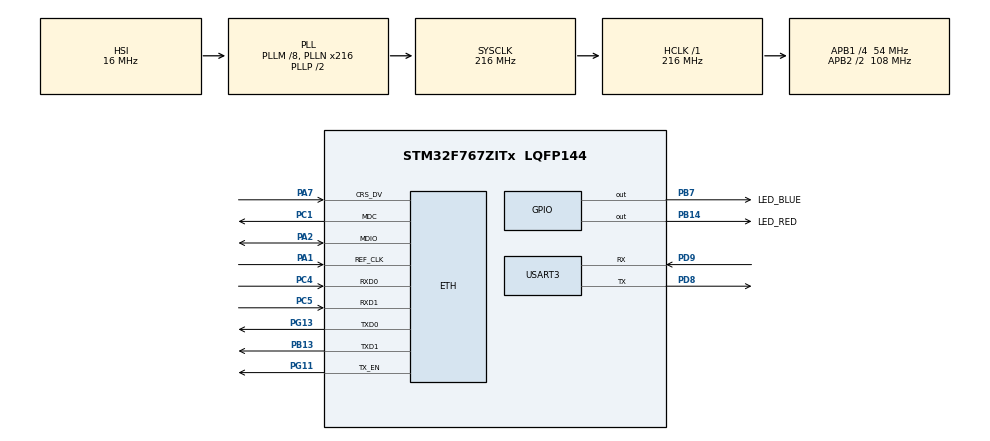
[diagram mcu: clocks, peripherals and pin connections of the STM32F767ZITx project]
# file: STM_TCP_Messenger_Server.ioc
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ETH.MediaInterface=ETH_MEDIA_INTERFACE_RMII
ETH.PhyAddress=0
FREERTOS.Mutexes01=MutexPrintf,Dynamic,NULL
FREERTOS.Tasks01=diagTask,24,128,StartdiagTask,Default,NULL,Dynamic,NULL,NULL
FREERTOS.configUSE_NEWLIB_REENTRANT=1
LWIP.LWIP_DHCP=1
LWIP.Version=v2.1.2_Cube
Mcu.Family=STM32F7
Mcu.Name=STM32F767ZITx
Mcu.Package=LQFP144
NVIC.ETH_IRQn=true\:5\:0\:false\:false\:true\:true\:false\:true\:true
NVIC.PriorityGroup=NVIC_PRIORITYGROUP_4
NVIC.TIM6_DAC_IRQn=true\:15\:0\:false\:false\:true\:false\:false\:true\:true
NVIC.TimeBase=TIM6_DAC_IRQn
NVIC.TimeBaseIP=TIM6
PA1.Mode=RMII
PA1.Signal=ETH_REF_CLK
PA13.Mode=Serial_Wire
PA13.Signal=SYS_JTMS-SWDIO
PA14.Mode=Serial_Wire
PA14.Signal=SYS_JTCK-SWCLK
PA2.Mode=RMII
PA2.Signal=ETH_MDIO
PA7.Mode=RMII
PA7.Signal=ETH_CRS_DV
PB13.Mode=RMII
PB13.Signal=ETH_TXD1
PB14.GPIO_Label=LED_RED
PB14.Signal=GPIO_Output
PB7.GPIO_Label=LED_BLUE
PB7.Signal=GPIO_Output
PC1.Mode=RMII
PC1.Signal=ETH_MDC
PC4.Mode=RMII
PC4.Signal=ETH_RXD0
PC5.Mode=RMII
PC5.Signal=ETH_RXD1
PD8.Mode=Asynchronous
PD8.Signal=USART3_TX
PD9.Mode=Asynchronous
PD9.Signal=USART3_RX
PG11.Mode=RMII
PG11.Signal=ETH_TX_EN
PG13.Mode=RMII
PG13.Signal=ETH_TXD0
ProjectManager.HeapSize=0x200
ProjectManager.StackSize=0x400
ProjectManager.TargetToolchain=STM32CubeIDE
RCC.AHBFreq_Value=216000000
RCC.APB1CLKDivider=RCC_HCLK_DIV4
RCC.APB1Freq_Value=54000000
RCC.APB1TimFreq_Value=108000000
RCC.APB2CLKDivider=RCC_HCLK_DIV2
RCC.APB2Freq_Value=108000000
RCC.APB2TimFreq_Value=216000000
RCC.CortexFreq_Value=216000000
RCC.HCLKFreq_Value=216000000
RCC.HSE_VALUE=25000000
RCC.HSI_VALUE=16000000
RCC.LSE_VALUE=32768
RCC.PLLM=8
RCC.PLLN=216
RCC.SYSCLKFreq_VALUE=216000000
RCC.SYSCLKSource=RCC_SYSCLKSOURCE_PLLCLK
RCC.USBFreq_Value=216000000
RCC.VCOOutputFreq_Value=432000000
USART3.VirtualMode-Asynchronous=VM_ASYNC
VP_FREERTOS_VS_CMSIS_V2.Mode=CMSIS_V2
VP_LWIP_VS_Enabled.Mode=Enabled
VP_SYS_VS_tim6.Mode=TIM6
board=custom

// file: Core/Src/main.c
/* USER CODE BEGIN Header */
/**
  ******************************************************************************
  * @file           : main.c
  * @brief          : Main program body
  ******************************************************************************
  * @attention
  *
  * Copyright (c) 2022 STMicroelectronics.
  * All rights reserved.
  *
  * This software is licensed under terms that can be found in the LICENSE file
  * in the root directory of this software component.
  * If no LICENSE file comes with this software, it is provided AS-IS.
  *
  ******************************************************************************
  */
/* USER CODE END Header */
#include "main.h"
#include "cmsis_os.h"
#include "lwip.h"
#include "usart.h"
#include "gpio.h"

void SystemClock_Config(void);
void MX_FREERTOS_Init(void);

int main(void)
{

  /* MCU Configuration--------------------------------------------------------*/

  /* Reset of all peripherals, Initializes the Flash interface and the Systick. */
  HAL_Init();

  /* Configure the system clock */
  SystemClock_Config();

  /* Initialize all configured peripherals */
  MX_GPIO_Init();
  MX_USART3_UART_Init();

  /* Init scheduler */
  osKernelInitialize();  /* Call init function for freertos objects (in freertos.c) */
  MX_FREERTOS_Init();

  /* Start scheduler */
  osKernelStart();

  /* We should never get here as control is now taken by the scheduler */
  /* Infinite loop */
  while (1)
  {

  }
}

void SystemClock_Config(void)
{
  RCC_OscInitTypeDef RCC_OscInitStruct = {0};
  RCC_ClkInitTypeDef RCC_ClkInitStruct = {0};

  /** Configure the main internal regulator output voltage
  */
  __HAL_RCC_PWR_CLK_ENABLE();
  __HAL_PWR_VOLTAGESCALING_CONFIG(PWR_REGULATOR_VOLTAGE_SCALE1);

  /** Initializes the RCC Oscillators according to the specified parameters
  * in the RCC_OscInitTypeDef structure.
  */
  RCC_OscInitStruct.OscillatorType = RCC_OSCILLATORTYPE_HSI;
  RCC_OscInitStruct.HSIState = RCC_HSI_ON;
  RCC_OscInitStruct.HSICalibrationValue = RCC_HSICALIBRATION_DEFAULT;
  RCC_OscInitStruct.PLL.PLLState = RCC_PLL_ON;
  RCC_OscInitStruct.PLL.PLLSource = RCC_PLLSOURCE_HSI;
  RCC_OscInitStruct.PLL.PLLM = 8;
  RCC_OscInitStruct.PLL.PLLN = 216;
  RCC_OscInitStruct.PLL.PLLP = RCC_PLLP_DIV2;
  RCC_OscInitStruct.PLL.PLLQ = 2;
  RCC_OscInitStruct.PLL.PLLR = 2;
  if (HAL_RCC_OscConfig(&RCC_OscInitStruct) != HAL_OK)
  {
    Error_Handler();
  }

  /** Activate the Over-Drive mode
  */
  if (HAL_PWREx_EnableOverDrive() != HAL_OK)
  {
    Error_Handler();
  }

  /** Initializes the CPU, AHB and APB buses clocks
  */
  RCC_ClkInitStruct.ClockType = RCC_CLOCKTYPE_HCLK|RCC_CLOCKTYPE_SYSCLK
                              |RCC_CLOCKTYPE_PCLK1|RCC_CLOCKTYPE_PCLK2;
  RCC_ClkInitStruct.SYSCLKSource = RCC_SYSCLKSOURCE_PLLCLK;
  RCC_ClkInitStruct.AHBCLKDivider = RCC_SYSCLK_DIV1;
  RCC_ClkInitStruct.APB1CLKDivider = RCC_HCLK_DIV4;
  RCC_ClkInitStruct.APB2CLKDivider = RCC_HCLK_DIV2;

  if (HAL_RCC_ClockConfig(&RCC_ClkInitStruct, FLASH_LATENCY_7) != HAL_OK)
  {
    Error_Handler();
  }
}

void HAL_TIM_PeriodElapsedCallback(TIM_HandleTypeDef *htim)
{
  if (htim->Instance == TIM6) {
    HAL_IncTick();
  }
}

void Error_Handler(void)
{
  __disable_irq();
  while (1)
  {
  }
}

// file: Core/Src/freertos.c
/* USER CODE BEGIN Header */
/**
  ******************************************************************************
  * File Name          : freertos.c
  * Description        : Code for freertos applications
  ******************************************************************************
  * @attention
  *
  * Copyright (c) 2022 STMicroelectronics.
  * All rights reserved.
  *
  * This software is licensed under terms that can be found in the LICENSE file
  * in the root directory of this software component.
  * If no LICENSE file comes with this software, it is provided AS-IS.
  *
  ******************************************************************************
  */
/* USER CODE END Header */

#include "FreeRTOS.h"
#include "task.h"
#include "main.h"
#include "cmsis_os.h"

/* USER CODE BEGIN Includes */
#include "tcp_server.h"
#include "usart.h"
/* USER CODE END Includes */

/* Definitions for diagTask */
osThreadId_t diagTaskHandle;
const osThreadAttr_t diagTask_attributes = {
  .name = "diagTask",
  .stack_size = 128 * 4,
  .priority = (osPriority_t) osPriorityNormal,
};
/* Definitions for MutexPrintf */
osMutexId_t MutexPrintfHandle;
const osMutexAttr_t MutexPrintf_attributes = {
  .name = "MutexPrintf"
};

void StartdiagTask(void *argument);

extern void MX_LWIP_Init(void);
void MX_FREERTOS_Init(void); /* (MISRA C 2004 rule 8.1) */

void MX_FREERTOS_Init(void) {
  /* Create the mutex(es) */
  /* creation of MutexPrintf */
  MutexPrintfHandle = osMutexNew(&MutexPrintf_attributes);

  /* Create the thread(s) */
  /* creation of diagTask */
  diagTaskHandle = osThreadNew(StartdiagTask, NULL, &diagTask_attributes);

}

void StartdiagTask(void *argument)
{
  /* init code for LWIP */
  MX_LWIP_Init();
  /* USER CODE BEGIN StartdiagTask */

  tcp_server_init();

  /* Infinite loop */
  for(;;)
  {
	HAL_GPIO_TogglePin(LED_BLUE_GPIO_Port, LED_BLUE_Pin);
    osDelay(500);
  }
  /* USER CODE END StartdiagTask */
}

/* USER CODE BEGIN Application */
void _putchar(char character)
{
  // send char to console etc.
	osMutexAcquire(MutexPrintfHandle, osWaitForever);
	HAL_UART_Transmit(&huart3, (uint8_t*)&character, 1, 1000);
	osMutexRelease(MutexPrintfHandle);
}
/* USER CODE END Application */
